# alb32r003x register map
Vendor: ALB; Series: ALB RT SoC
CPU: ALB XF, little endian
Registers are 32-bit, access not given, reset 0x0 unless marked. A register's access mark holds for its fields unless they carry their own. Offsets are from the block's base; [hi:lo] are bit positions; {n}, {i} and the like mark numbered series.

## MTIMER — System Timer.
Base 0xE0030000
0x00 MTIME_LO rw — Machine Timer Register Low.
0x04 MTIME_HI rw — Machine Timer Register High.
0x08 MTIMECMP_LO rw — Machine Timer Compare Register Low.
0x0C MTIMECMP_HI rw — Machine Timer Compare Register High.
0xFF0 MSFTRST rw — Machine Timer Software Core Reset Register.
0xFF8 MIMECTL rw — Machine Timer Control Register.
0xFFC MSIP rw — Machine Software Interrupt Pending Register.

## ADCA_RESULT
Base 0x20800000
Same registers: ADCB_RESULT 0x20800200, ADCC_RESULT 0x20800400
{0x0+2i} ADCRESULT{i} 16-bit (i=0..15)
  [15:0] ADC{i}_RESULT — ADC结果{i},12bitADC结果.
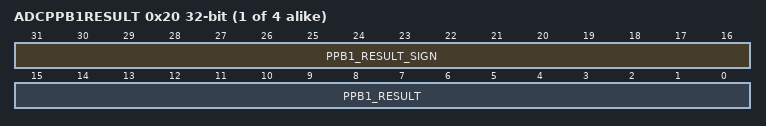
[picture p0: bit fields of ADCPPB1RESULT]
{0x1C+4i} ADCPPB{i}RESULT (i=1..4)
  [31:16] PPB{i}_RESULT_SIGN — Sign Extended Bits. These bits reflect the same value as bit 16.
  [15:0] PPB{i}_RESULT — ADC Post Processing Block Result {i}

## DAC1 — DAC: Digital-to-Analog Converter
Base 0x21040000
Same registers: DAC2 0x21040400
0x00 REV — REV:DAC Revision Register
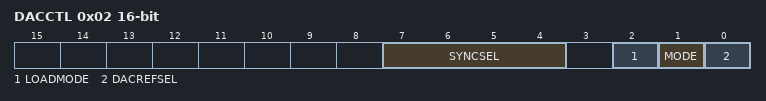
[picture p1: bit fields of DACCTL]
0x02 DACCTL 16-bit
  [7:4] SYNCSEL — DAC EPWMSYNCPER select. Determines which EPWMSYNCPER
  [2] LOADMODE — DACVALA load mode. Determines when the DACVALA register is
  [1] MODE — DAC gain mode select. Selects the gain mode for the buffered
  [0] DACREFSEL — DAC reference select. Selects which voltage references are used by
0x04 DACVALA 16-bit
  [11:0] DACVALA — Active output code currently driven by the DAC
0x06 DACVALS 16-bit
  [11:0] DACVALS — Shadow output code to be loaded into DACVALA
0x08 DACOUTEN 16-bit
  [0] DACOUTEN — DAC output enable
0x0A LOCK — LOCK: DAC Lock Register
0x0C TRIM — TRIM: DAC Value Register - Active

## AES — AES: Advanced Encryption Standard accelerator for secure data processing
Base 0x22000000
0x00 AES — AES: Advanced Encryption Standard accelerator for secure data processing
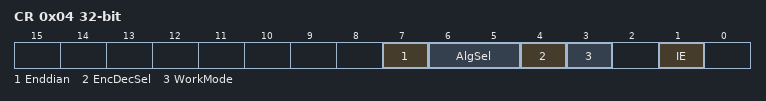
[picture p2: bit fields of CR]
0x04 CR rw — CR: AES control register selecting mode, key size and operation start
  [7] Enddian
    0=LITTLE (Little-Enddian mode); 1=BIG (Big-Enddian mode)
  [6:5] AlgSel
    1=128-bit Key; 2=192-bit Key; 3=256-bit Key
  [4] EncDecSel
    0=Encryption; 1=Decryption
  [3] WorkMode
    0=ECB (ECB mode); 1=CBC (CBC mode)
  [1] IE — Interrupt enable bit
    0=DISABLED (disable interrupts); 1=ENABLED (enable interrupts)
0x08 ISR — ISR: AES interrupt status register indicating operation complete and error events
{0x10+4i} DINR{i} (i=0..3) — DINR{i}: AES input data register {i} for 32-bit plaintext/ciphertext word
{0x20+4i} DOUTR{i} (i=0..3) — DOUTR{i}: AES output data register {i} for 32-bit result word
{0x30+4i} KEYR{i} (i=0..7) — KEYR{i}: AES key register {i} for 32-bit encryption/decryption key word
{0x50+4i} IVR{i} (i=0..3) — IVR{i}: AES initialization-vector register {i} for 32-bit IV word

## DMA1_CH1
Base 0x23002000
Same registers: DMA1_CH2 0x23002058, DMA1_CH3 0x230020B0, DMA1_CH4 0x23002108
0x00 SAR_L
  [31:0] SAR — Source Address Register
0x04 SAR_H
0x08 DAR_L
  [31:0] DAR — Destination Address Register
0x0C DAR_H
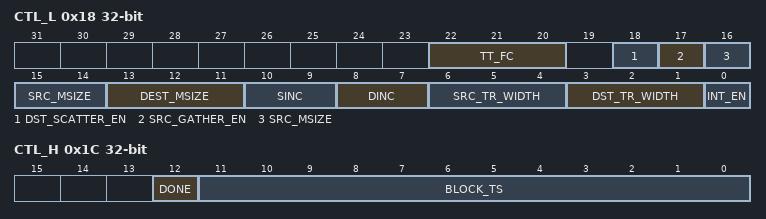
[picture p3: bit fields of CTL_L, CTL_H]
0x18 CTL_L
  [22:20] TT_FC — Transfer Type and Flow Control
  [18] DST_SCATTER_EN — Destination scatter enable
  [17] SRC_GATHER_EN — Source gather enable.
  [16:14] SRC_MSIZE — Source Burst Transaction Length
  [13:11] DEST_MSIZE — Destination Burst Transaction Length
  [10:9] SINC — Source Address Increment
  [8:7] DINC — Destination Address Increment
  [6:4] SRC_TR_WIDTH — Source Transfer Width
  [3:1] DST_TR_WIDTH — Destination Transfer Width
  [0] INT_EN — Interrupt Enable
0x1C CTL_H
  [12] DONE
  [11:0] BLOCK_TS — Block Transfer Size
0x40 CFG_L
0x44 CFG_H

## DMA2_CH1
Base 0x23003000
Same registers: DMA2_CH2 0x23003058, DMA2_CH3 0x230030B0, DMA2_CH4 0x23003108
Registers as DMA1_CH1; these are added or differ:
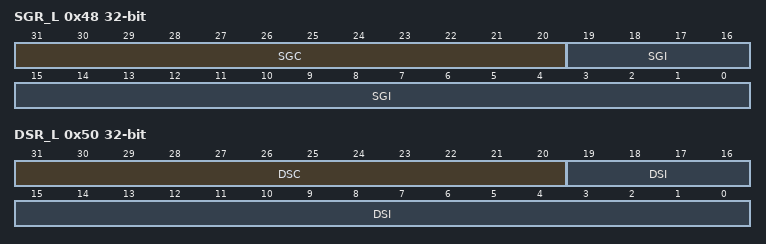
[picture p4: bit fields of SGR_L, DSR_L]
0x48 SGR_L
  [31:20] SGC — Source Gather Count
  [19:0] SGI — Source Gather Interval
0x4C SGR_H
0x50 DSR_L
  [31:20] DSC — Destination Scatter Count
  [19:0] DSI — Destination Scatter Interval
0x54 DSR_H
